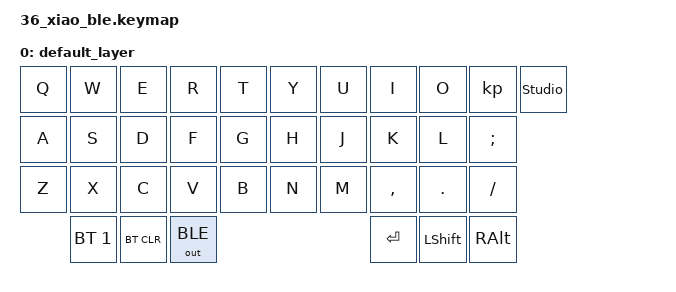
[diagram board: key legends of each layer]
#include <behaviors.dtsi>
#include <dt-bindings/zmk/keys.h>
#include <dt-bindings/zmk/bt.h>
##include <dt-bindings/zmk/outputs.h>

/ {
        keymap {
                compatible = "zmk,keymap";

                default_layer {
// -----------------------------------------------------------------------------------------
// |  TAB |  Q  |  W  |  E  |  R  |  T  |   |  Y  |  U   |  I  |  O  |  P  | BKSP |
// | CTRL |  A  |  S  |  D  |  F  |  G  |   |  H  |  J   |  K  |  L  |  ;  |  '   |
// | SHFT |  Z  |  X  |  C  |  V  |  B  |   |  N  |  M   |  ,  |  .  |  /  | ESC  |
//                    | GUI | LWR | SPC |   | ENT | RSE  | ALT |
                        bindings = <
   &kp Q &kp W &kp E &kp R &kp T   &kp Y &kp U  &kp I     &kp O   &kp &studio_unlock   
   &kp A &kp S &kp D &kp F &kp G   &kp H &kp J  &kp K     &kp L   &kp SEMI
   &kp Z &kp X &kp C &kp V &kp B   &kp N &kp M  &kp COMMA &kp DOT &kp FSLH
        &bt BT_SEL 1 &bt BT_CLR &out OUT_BLE   &kp RET &kp LSHIFT &kp RALT
                        >;
                };
        };
};
